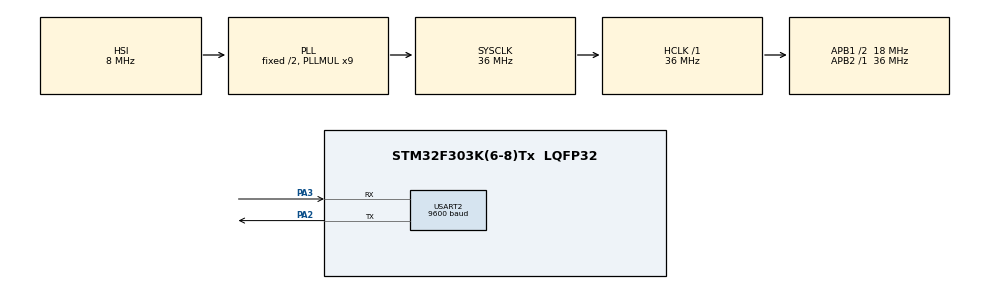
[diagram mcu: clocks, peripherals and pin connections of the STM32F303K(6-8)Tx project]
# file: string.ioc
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Mcu.Family=STM32F3
Mcu.Name=STM32F303K(6-8)Tx
Mcu.Package=LQFP32
NVIC.PriorityGroup=NVIC_PRIORITYGROUP_4
PA13.GPIO_Label=SWDIO
PA13.Mode=Serial_Wire
PA13.Signal=SYS_JTMS-SWDIO
PA14.GPIO_Label=SWCLK
PA14.Mode=Serial_Wire
PA14.Signal=SYS_JTCK-SWCLK
PA2.Mode=Asynchronous
PA2.Signal=USART2_TX
PA3.Mode=Asynchronous
PA3.Signal=USART2_RX
PF0\ /\ OSC_IN.GPIO_Label=MCO
PF0\ /\ OSC_IN.Signal=RCC_OSC_IN
ProjectManager.HeapSize=0x200
ProjectManager.StackSize=0x400
ProjectManager.TargetToolchain=MDK-ARM V5
RCC.AHBFreq_Value=36000000
RCC.APB1CLKDivider=RCC_HCLK_DIV2
RCC.APB1Freq_Value=18000000
RCC.APB1TimFreq_Value=36000000
RCC.APB2Freq_Value=36000000
RCC.APB2TimFreq_Value=36000000
RCC.CortexFreq_Value=36000000
RCC.HCLKFreq_Value=36000000
RCC.HSI_VALUE=8000000
RCC.PLLMUL=RCC_PLL_MUL9
RCC.SYSCLKFreq_VALUE=36000000
RCC.SYSCLKSourceVirtual=RCC_SYSCLKSOURCE_PLLCLK
USART2.BaudRate=9600
USART2.VirtualMode-Asynchronous=VM_ASYNC
board=NUCLEO-F303K8

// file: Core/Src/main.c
/* USER CODE BEGIN Header */
/**
  ******************************************************************************
  * @file           : main.c
  * @brief          : Main program body
  ******************************************************************************
  * @attention
  *
  * <h2><center>&copy; Copyright (c) 2021 STMicroelectronics.
  * All rights reserved.</center></h2>
  *
  * This software component is licensed by ST under BSD 3-Clause license,
  * the "License"; You may not use this file except in compliance with the
  * License. You may obtain a copy of the License at:
  *                        opensource.org/licenses/BSD-3-Clause
  *
  ******************************************************************************
  */
/* USER CODE END Header */
#include "main.h"

/* USER CODE BEGIN Includes */
#include "stdio.h"

/* USER CODE END Includes */

UART_HandleTypeDef huart2;

void SystemClock_Config(void);
static void MX_GPIO_Init(void);
static void MX_USART2_UART_Init(void);

/* USER CODE BEGIN 0 */
int i=0;
char ItoSTR[10]={0};
uint8_t Cmd_End[3]={0xFF, 0xFF, 0xFF};//command end sequence
void NEXTION_SendString (char *ID, char *string)
{
	char buf[50];
	int len=sprintf (buf, "%s.txt=\"%s\"", ID, string);
	HAL_UART_Transmit (&huart2, (uint8_t *)buf, len, 1000);
	HAL_UART_Transmit (&huart2, Cmd_End, 3, 100);
}
/* USER CODE END 0 */

int main(void)
{

  /* MCU Configuration--------------------------------------------------------*/

  /* Reset of all peripherals, Initializes the Flash interface and the Systick. */
  HAL_Init();

  /* Configure the system clock */
  SystemClock_Config();

  /* Initialize all configured peripherals */
  MX_GPIO_Init();
  MX_USART2_UART_Init();
  /* USER CODE BEGIN 2 */
	HAL_Delay (1000);
	NEXTION_SendString ("t0", "Hi dick!");
	HAL_Delay (1000);

  /* USER CODE END 2 */

  /* Infinite loop */
  while (1)
  {

    /* USER CODE BEGIN 3 */
		sprintf (ItoSTR, "%d", i);
		NEXTION_SendString ("t0", ItoSTR);
		HAL_Delay (1000);
		i++;
		if (i==1000)
			i=0;
  }
  /* USER CODE END 3 */
}

void SystemClock_Config(void)
{
  RCC_OscInitTypeDef RCC_OscInitStruct = {0};
  RCC_ClkInitTypeDef RCC_ClkInitStruct = {0};

  /** Initializes the RCC Oscillators according to the specified parameters
  * in the RCC_OscInitTypeDef structure.
  */
  RCC_OscInitStruct.OscillatorType = RCC_OSCILLATORTYPE_HSI;
  RCC_OscInitStruct.HSIState = RCC_HSI_ON;
  RCC_OscInitStruct.HSICalibrationValue = RCC_HSICALIBRATION_DEFAULT;
  RCC_OscInitStruct.PLL.PLLState = RCC_PLL_ON;
  RCC_OscInitStruct.PLL.PLLSource = RCC_PLLSOURCE_HSI;
  RCC_OscInitStruct.PLL.PLLMUL = RCC_PLL_MUL9;
  if (HAL_RCC_OscConfig(&RCC_OscInitStruct) != HAL_OK)
  {
    Error_Handler();
  }
  /** Initializes the CPU, AHB and APB buses clocks
  */
  RCC_ClkInitStruct.ClockType = RCC_CLOCKTYPE_HCLK|RCC_CLOCKTYPE_SYSCLK
                              |RCC_CLOCKTYPE_PCLK1|RCC_CLOCKTYPE_PCLK2;
  RCC_ClkInitStruct.SYSCLKSource = RCC_SYSCLKSOURCE_PLLCLK;
  RCC_ClkInitStruct.AHBCLKDivider = RCC_SYSCLK_DIV1;
  RCC_ClkInitStruct.APB1CLKDivider = RCC_HCLK_DIV2;
  RCC_ClkInitStruct.APB2CLKDivider = RCC_HCLK_DIV1;

  if (HAL_RCC_ClockConfig(&RCC_ClkInitStruct, FLASH_LATENCY_1) != HAL_OK)
  {
    Error_Handler();
  }
}

static void MX_USART2_UART_Init(void)
{

  huart2.Instance = USART2;
  huart2.Init.BaudRate = 9600;
  huart2.Init.WordLength = UART_WORDLENGTH_8B;
  huart2.Init.StopBits = UART_STOPBITS_1;
  huart2.Init.Parity = UART_PARITY_NONE;
  huart2.Init.Mode = UART_MODE_TX_RX;
  huart2.Init.HwFlowCtl = UART_HWCONTROL_NONE;
  huart2.Init.OverSampling = UART_OVERSAMPLING_16;
  huart2.Init.OneBitSampling = UART_ONE_BIT_SAMPLE_DISABLE;
  huart2.AdvancedInit.AdvFeatureInit = UART_ADVFEATURE_NO_INIT;
  if (HAL_UART_Init(&huart2) != HAL_OK)
  {
    Error_Handler();
  }

}

static void MX_GPIO_Init(void)
{

  /* GPIO Ports Clock Enable */
  __HAL_RCC_GPIOF_CLK_ENABLE();
  __HAL_RCC_GPIOA_CLK_ENABLE();

}

void Error_Handler(void)
{
  __disable_irq();
  while (1)
  {
  }
}

/************************ (C) COPYRIGHT STMicroelectronics *****END OF FILE****/
